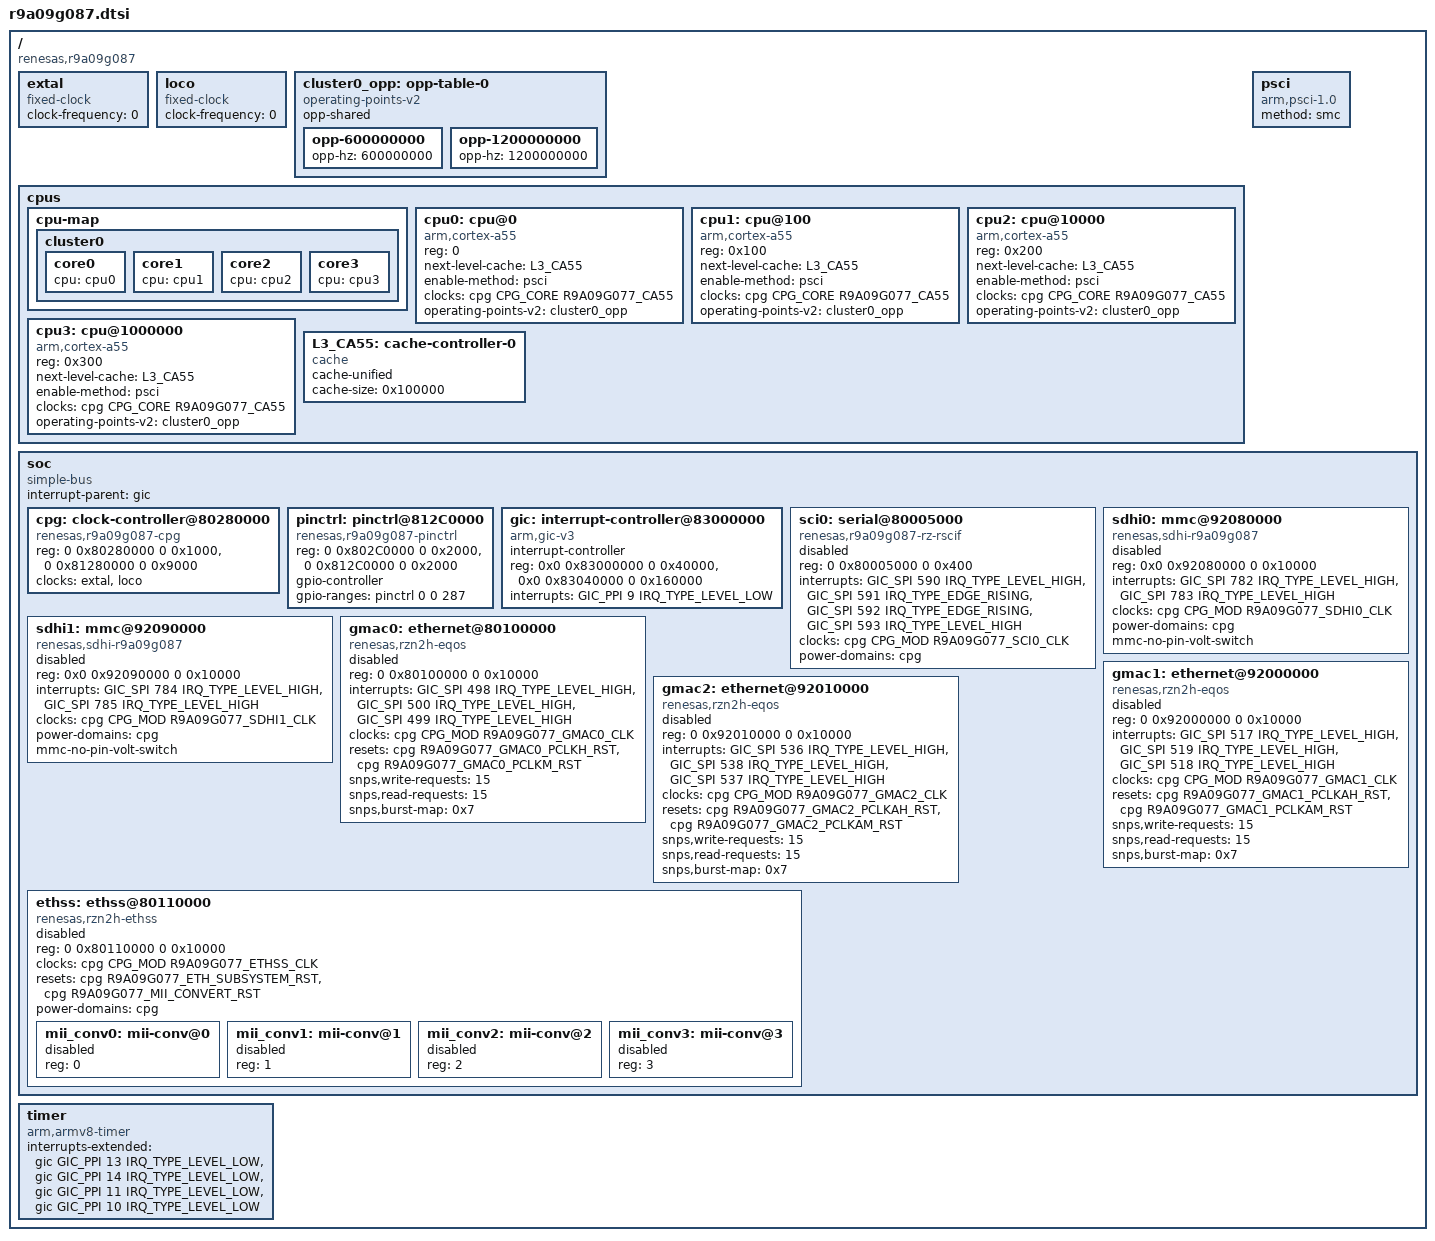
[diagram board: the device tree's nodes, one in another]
// SPDX-License-Identifier: (GPL-2.0-only OR BSD-2-Clause)
/*
 * Device Tree Source for the RZ/N2H SoC
 *
 * Copyright (C) 2025 Renesas Electronics Corp.
 */

#include <dt-bindings/interrupt-controller/arm-gic.h>
#include <dt-bindings/clock/r9a09g077-cpg.h>

/ {
	compatible = "renesas,r9a09g087";
	#address-cells = <2>;
	#size-cells = <2>;

	extal: extal {
		compatible = "fixed-clock";
		#clock-cells = <0>;
		/* This value must be overridden by the board */
		clock-frequency = <0>;
	};

	loco: loco {
		compatible = "fixed-clock";
		#clock-cells = <0>;
		/* This value must be overridden by the board */
		clock-frequency = <0>;
	};

	cluster0_opp: opp-table-0 {
		compatible = "operating-points-v2";
		opp-shared;

		opp-600000000 {
			opp-hz = /bits/ 64 <600000000>;
		};
		opp-1200000000 {
			opp-hz = /bits/ 64 <1200000000>;
		};
	};

	cpus {
		#address-cells = <1>;
		#size-cells = <0>;

		cpu-map {
			cluster0 {
				core0 {
					cpu = <&cpu0>;
				};
				core1 {
					cpu = <&cpu1>;
				};
				core2 {
					cpu = <&cpu2>;
				};
				core3 {
					cpu = <&cpu3>;
				};
			};
		};

		cpu0: cpu@0 {
			compatible = "arm,cortex-a55";
			reg = <0>;
			device_type = "cpu";
			next-level-cache = <&L3_CA55>;
			enable-method = "psci";
			clocks = <&cpg CPG_CORE R9A09G077_CA55>;
			operating-points-v2 = <&cluster0_opp>;
		};

		cpu1: cpu@100 {
			compatible = "arm,cortex-a55";
			reg = <0x100>;
			device_type = "cpu";
			next-level-cache = <&L3_CA55>;
			enable-method = "psci";
			clocks = <&cpg CPG_CORE R9A09G077_CA55>;
			operating-points-v2 = <&cluster0_opp>;
		};

		cpu2: cpu@10000 {
			compatible = "arm,cortex-a55";
			reg = <0x200>;
			device_type = "cpu";
			next-level-cache = <&L3_CA55>;
			enable-method = "psci";
			clocks = <&cpg CPG_CORE R9A09G077_CA55>;
			operating-points-v2 = <&cluster0_opp>;
		};

		cpu3: cpu@1000000 {
			compatible = "arm,cortex-a55";
			reg = <0x300>;
			device_type = "cpu";
			next-level-cache = <&L3_CA55>;
			enable-method = "psci";
			clocks = <&cpg CPG_CORE R9A09G077_CA55>;
			operating-points-v2 = <&cluster0_opp>;
		};

		L3_CA55: cache-controller-0 {
			compatible = "cache";
			cache-unified;
			cache-size = <0x100000>;
		};
	};

	psci {
		compatible = "arm,psci-1.0", "arm,psci-0.2";
		method = "smc";
	};

	soc: soc {
		compatible = "simple-bus";
		interrupt-parent = <&gic>;
		#address-cells = <2>;
		#size-cells = <2>;
		ranges;

		cpg: clock-controller@80280000 {
			compatible = "renesas,r9a09g087-cpg";
			reg = <0 0x80280000 0 0x1000>,
			      <0 0x81280000 0 0x9000>;
			clocks = <&extal>, <&loco>;
			clock-names = "extal", "loco";
			#clock-cells = <2>;
			#reset-cells = <1>;
			#power-domain-cells = <0>;
		};

		pinctrl: pinctrl@812C0000 {
			compatible = "renesas,r9a09g087-pinctrl";
			reg = <0 0x802C0000 0 0x2000>,
			      <0 0x812C0000 0 0x2000>;
			gpio-controller;
			#gpio-cells = <2>;
			gpio-ranges = <&pinctrl 0 0 287>;
		};

		gic: interrupt-controller@83000000 {
			compatible = "arm,gic-v3";
			#interrupt-cells = <3>;
			#address-cells = <0>;
			interrupt-controller;
			reg = <0x0 0x83000000 0 0x40000>,
			      <0x0 0x83040000 0 0x160000>;
			interrupts = <GIC_PPI 9 IRQ_TYPE_LEVEL_LOW>;
		};

		sci0: serial@80005000 {
			compatible = "renesas,r9a09g087-rz-rscif",
				     "renesas,rz-rscif";
			reg = <0 0x80005000 0 0x400>;
			interrupts = <GIC_SPI 590 IRQ_TYPE_LEVEL_HIGH>,
				     <GIC_SPI 591 IRQ_TYPE_EDGE_RISING>,
				     <GIC_SPI 592 IRQ_TYPE_EDGE_RISING>,
				     <GIC_SPI 593 IRQ_TYPE_LEVEL_HIGH>;
			interrupt-names = "eri", "rxi", "txi", "tei";
			clocks = <&cpg CPG_MOD R9A09G077_SCI0_CLK>;
			clock-names = "fck";
			power-domains = <&cpg>;
			status = "disabled";
		};

		sdhi0: mmc@92080000 {
			compatible = "renesas,sdhi-r9a09g087",
				     "renesas,rcar-gen3-sdhi";
			reg = <0x0 0x92080000 0 0x10000>;
			interrupts = <GIC_SPI 782 IRQ_TYPE_LEVEL_HIGH>,
				     <GIC_SPI 783 IRQ_TYPE_LEVEL_HIGH>;
			clocks = <&cpg CPG_MOD R9A09G077_SDHI0_CLK>;
			clock-names = "clk";
			power-domains = <&cpg>;
			mmc-no-pin-volt-switch;
			status = "disabled";
		};

		sdhi1: mmc@92090000 {
			compatible = "renesas,sdhi-r9a09g087",
				     "renesas,rcar-gen3-sdhi";
			reg = <0x0 0x92090000 0 0x10000>;
			interrupts = <GIC_SPI 784 IRQ_TYPE_LEVEL_HIGH>,
				     <GIC_SPI 785 IRQ_TYPE_LEVEL_HIGH>;
			clocks = <&cpg CPG_MOD R9A09G077_SDHI1_CLK>;
			clock-names = "clk";
			power-domains = <&cpg>;
			mmc-no-pin-volt-switch;
			status = "disabled";
		};

		gmac0: ethernet@80100000 {
			compatible = "renesas,rzn2h-eqos",
				     "snps,dwc-qos-ethernet-4.10";
			reg = <0 0x80100000 0 0x10000>;
			interrupts = <GIC_SPI 498 IRQ_TYPE_LEVEL_HIGH>,
				     <GIC_SPI 500 IRQ_TYPE_LEVEL_HIGH>,
				     <GIC_SPI 499 IRQ_TYPE_LEVEL_HIGH>;
			interrupt-names = "macirq", "eth_wake_irq", "eth_lpi";
			clocks = <&cpg CPG_MOD R9A09G077_GMAC0_CLK>;
			clock-names = "clk";
			resets = <&cpg R9A09G077_GMAC0_PCLKH_RST>,
				 <&cpg R9A09G077_GMAC0_PCLKM_RST>;
			reset-names = "reset_h", "reset_m";
			#address-cells = <1>;
			#size-cells = <0>;
			status = "disabled";
			snps,write-requests = <15>;
			snps,read-requests = <15>;
			snps,burst-map = <0x7>;
		};

		gmac1: ethernet@92000000 {
			compatible = "renesas,rzn2h-eqos",
				     "snps,dwc-qos-ethernet-4.10";
			reg = <0 0x92000000 0 0x10000>;
			interrupts = <GIC_SPI 517 IRQ_TYPE_LEVEL_HIGH>,
				     <GIC_SPI 519 IRQ_TYPE_LEVEL_HIGH>,
				     <GIC_SPI 518 IRQ_TYPE_LEVEL_HIGH>;
			interrupt-names = "macirq", "eth_wake_irq", "eth_lpi";
			clocks = <&cpg CPG_MOD R9A09G077_GMAC1_CLK>;
			clock-names = "clk";
			resets = <&cpg R9A09G077_GMAC1_PCLKAH_RST>,
				 <&cpg R9A09G077_GMAC1_PCLKAM_RST>;
			reset-names = "reset_h", "reset_m";
			#address-cells = <1>;
			#size-cells = <0>;
			status = "disabled";
			snps,write-requests = <15>;
			snps,read-requests = <15>;
			snps,burst-map = <0x7>;
		};

		gmac2: ethernet@92010000 {
			compatible = "renesas,rzn2h-eqos",
				     "snps,dwc-qos-ethernet-4.10";
			reg = <0 0x92010000 0 0x10000>;
			interrupts = <GIC_SPI 536 IRQ_TYPE_LEVEL_HIGH>,
				     <GIC_SPI 538 IRQ_TYPE_LEVEL_HIGH>,
				     <GIC_SPI 537 IRQ_TYPE_LEVEL_HIGH>;
			interrupt-names = "macirq", "eth_wake_irq", "eth_lpi";
			clocks = <&cpg CPG_MOD R9A09G077_GMAC2_CLK>;
			clock-names = "clk";
			resets = <&cpg R9A09G077_GMAC2_PCLKAH_RST>,
				 <&cpg R9A09G077_GMAC2_PCLKAM_RST>;
			reset-names = "reset_h", "reset_m";
			#address-cells = <1>;
			#size-cells = <0>;
			status = "disabled";
			snps,write-requests = <15>;
			snps,read-requests = <15>;
			snps,burst-map = <0x7>;
		};

		ethss: ethss@80110000 {
			compatible = "renesas,rzn2h-ethss";
			#address-cells = <1>;
			#size-cells = <0>;
			reg =  <0 0x80110000 0 0x10000>;
			clocks = <&cpg CPG_MOD R9A09G077_ETHSS_CLK>;
			resets = <&cpg R9A09G077_ETH_SUBSYSTEM_RST>,
				 <&cpg R9A09G077_MII_CONVERT_RST>;
			reset-names = "reset_ethss", "reset_conv";
			power-domains = <&cpg>;
			status = "disabled";

			mii_conv0: mii-conv@0 {
				reg = <0>;
				status = "disabled";
			};

			mii_conv1: mii-conv@1 {
				reg = <1>;
				status = "disabled";
			};

			mii_conv2: mii-conv@2 {
				reg = <2>;
				status = "disabled";
			};

			mii_conv3: mii-conv@3 {
				reg = <3>;
				status = "disabled";
			};
		};
	};

	timer {
		compatible = "arm,armv8-timer";
		interrupts-extended = <&gic GIC_PPI 13 IRQ_TYPE_LEVEL_LOW>,
				      <&gic GIC_PPI 14 IRQ_TYPE_LEVEL_LOW>,
				      <&gic GIC_PPI 11 IRQ_TYPE_LEVEL_LOW>,
				      <&gic GIC_PPI 10 IRQ_TYPE_LEVEL_LOW>;
	};
};
